# ADuCM410 register map
Vendor: Analog Devices; Series: ADuCM410; File version: 1p0
CPU: CM33 r0p1, little endian, MPU, FPU, 3 interrupt priority bits
Registers are 32-bit, read-write, reset 0x0 unless marked. A register's access mark holds for its fields unless they carry their own. Offsets are from the block's base; [hi:lo] are bit positions; {n}, {i} and the like mark numbered series; 'fields as' and 'values as' point back to an identical list.

## SRAM
Base 0x40065000
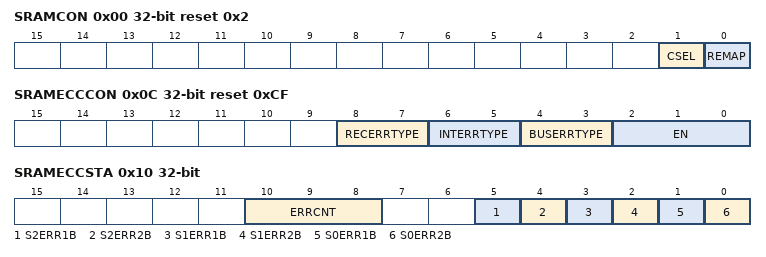
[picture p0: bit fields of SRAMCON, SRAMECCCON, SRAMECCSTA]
0x00 SRAMCON reset 0x2 — SRAM Control Register
  [1] CSEL — Use Cache as a Part of SRAM0
    0=NCAS (Cache not as SRAM); 1=CAS (Cache as SRAM)
  [0] REMAP — Using SRAM0 as Instruction SRAM
    0=CODRAM (Using as Code SRAM); 1=SYSRAM (Using as System SRAM)
0x0C SRAMECCCON reset 0xCF — SRAM ECC Control Register
  [8:7] RECERRTYPE — ECC Error Address and Data Record Type
    0=CURERR (Return Current Error Address and Data Information); 1=STRERR0 (Return Stored Error Address and Data Information); 2=STRERR12 (Return Stored Error Address and Data Information); 3=STRERR13 (Return Stored Error Address and Data Information)
  [6:5] INTERRTYPE — ECC Interrupt Error Response Type
    0=NOERR (No Error Report); 1=ERR2B (2 Bits Error Report); 2=ERR1B (1 Bit Error Report); 3=ALERR (1 or 2 Bits Error Report)
  [4:3] BUSERRTYPE — ECC AHB Bus Error Response Type
    values as INTERRTYPE
  [2:0] EN — ECC Check Enable
    0=ENNA (None SRAM ECC Enable); 1=SRAM0 ECC Enable; 2=SRAM1 ECC Enable; 3=SRAM0 and SRAM1 ECC Enable; 4=SRAM2 ECC Enable; 5=SRAM0 and SRAM2 ECC Enable; 6=SRAM1 and SRAM2 ECC Enable; 7=SRAM0 and SRAM1 and SRAM2 ECC Enable
0x10 SRAMECCSTA — SRAM ECC Status Register
  [10:8] ERRCNT ro — ECC Error Counter
  [5] S2ERR1B ro — SRAM2 ECC 1 Bits Error
  [4] S2ERR2B ro — SRAM2 ECC 2 Bits Error
  [3] S1ERR1B ro — SRAM1 ECC 1 Bit Error
  [2] S1ERR2B ro — SRAM1 ECC 2 Bits Error
  [1] S0ERR1B ro — SRAM0 ECC 1 Bit Error
  [0] S0ERR2B ro — SRAM0 ECC 2 Bits Error
{0x14+0xC*i} SRAMECCA{i} (i=0..2) — SRAM{i} ECC Error Address Register
  [31:0] ADDR ro — ECC Error Address
{0x18+0xC*i} SRAMECCD{i} (i=0..2) — SRAM{i} ECC Error Data Register
  [31:0] DATA ro — ECC Error Raw Data
{0x1C+0xC*i} SRAMECCP{i} (i=0..2) — SRAM{i} ECC Error Parity Register
  [6:0] PARITY ro — ECC Error Raw Parity

## CRC
Base 0x40066000
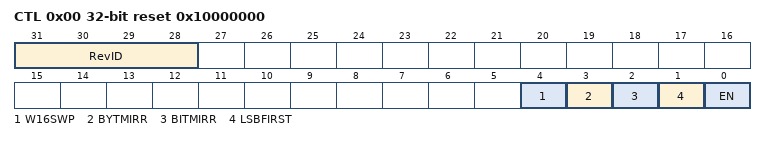
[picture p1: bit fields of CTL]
0x00 CTL reset 0x10000000 — CRC Control Register
  [31:28] RevID ro — Revision ID
  [4] W16SWP range 0x00000000..0x00000001 — Word16 Swap
  [3] BYTMIRR range 0x00000000..0x00000001 — Byte Mirroring
  [2] BITMIRR range 0x00000000..0x00000001 — Bit Mirroring
  [1] LSBFIRST range 0x00000000..0x00000001 — LSB First Calculation Order
  [0] EN range 0x00000000..0x00000001 — CRC Peripheral Enable
0x04 IPDATA — Input Data Word Register
  [31:0] DATA_WORD wo range 0x00000000..0xFFFFFFFF — Data Input.
0x08 RESULT — CRC Result Register
  [31:0] RESIDUE range 0x00000000..0xFFFFFFFF — CRC Residue
0x0C POLY reset 0x4C11DB7 — Programmable CRC Polynomial
  [31:0] REDUCTION_POLY range 0x00000000..0xFFFFFFFF — CRC Reduction Polynomial

## COMP
Base 0x40068A00
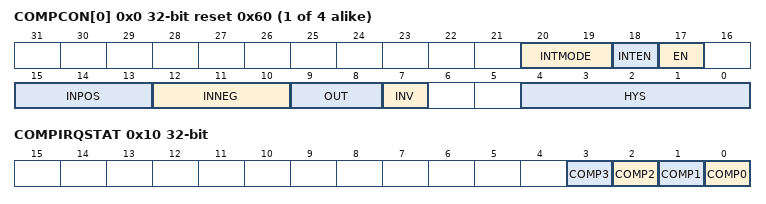
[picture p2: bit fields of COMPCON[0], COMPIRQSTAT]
{0x0+4i} COMPCON[{i}] (i=0..3) reset 0x60
  [20:19] INTMODE — Interrupt Mode
    0=RISEEDGE (Generate Interrupt if Rising Edge Happens); 1=FALLEDGE (Generate Interrupt if Falling Edge Happens); 2=LOWLEVEL (Generate Interrupt if Low Level Happens); 3=HIGHLEVEL (Generate Interrupt if High Level Happens)
  [18] INTEN range 0x00000000..0x00000001 — Interrupt Enable
  [17] EN range 0x00000000..0x00000001 — Enable Comparator
  [15:13] INPOS — Select Comparator Positive Input Source
    0=NO_INPUT (All Input Switches Off); 1=AINxP (Enable AIN8/10/12/14 for comp 0/1/2/3); 2=PGAIN (Enable PGA0/1/2/3 for comp 0/1/2/3); 3=GPIO_ANAIN (Enable GPIO0.6/0.7/2.0/2.1 Analog Signal Input for comp 0/1/2/3)
  [12:10] INNEG — Select Comparator Negative Input Source
    0=NO_INPUT (All Input Switches Off); 1=AHIDIV2IN (Enable Half Avdd Input); 2=AINxN (Enable AIN9/11/13/15 for Comp 0/1/2/3); {v}=VDAC{v+5}IN (Enable VDAC{v+5} Input) (v=3..6); 7=V1P25REFIN (Enable 1.25V Ref Input from AIN15(BUF1))
  [9:8] OUT — Comp Interrupt Select
    0=DIS00 (Output to Test Pad Disable); 1=DIS01 (Output to Test Pad Disable); 2=EN10 (Output to Test Pad Enable); 3=DIS11 (Output to Test Pad Disable)
  [7] INV — Select Output Logic State
    0=NOM (Output is High if +ve is higher than -ve input); 1=COV (Output is High if -ve is higher than +ve input)
  [4:0] HYS — Comp Hysteresis Register
    0=DIS (hysteresis disabled); 1=EN10MV (10mv hysteresis enabled); 2=EN25MV (25mv hysteresis); 3=EN35MV (35mv hysteresis); 6=EN50MV (50mv hysteresis); 7=EN60MV (60mv hysteresis); 12=EN75MV (75mv hysteresis); 13=EN85MV (85mv hysteresis); 14=EN100MV (100mv hysteresis); 17=EN110MV (110mv hysteresis); 18=EN125MV (125mv hysteresis); 19=EN135MV (135mv hysteresis); 22=EN150MV (150mv hysteresis); 23=EN160MV (160mv hysteresis); 28=EN175MV (175mv hysteresis); 29=EN185MV (185mv hysteresis); 30=EN200MV (200mv hysteresis); 31=EN210MV (210mv hysteresis)
0x10 COMPIRQSTAT
  [n] COMP{n} ro (n=0..3) — Comparator {n} Interrupt Status
